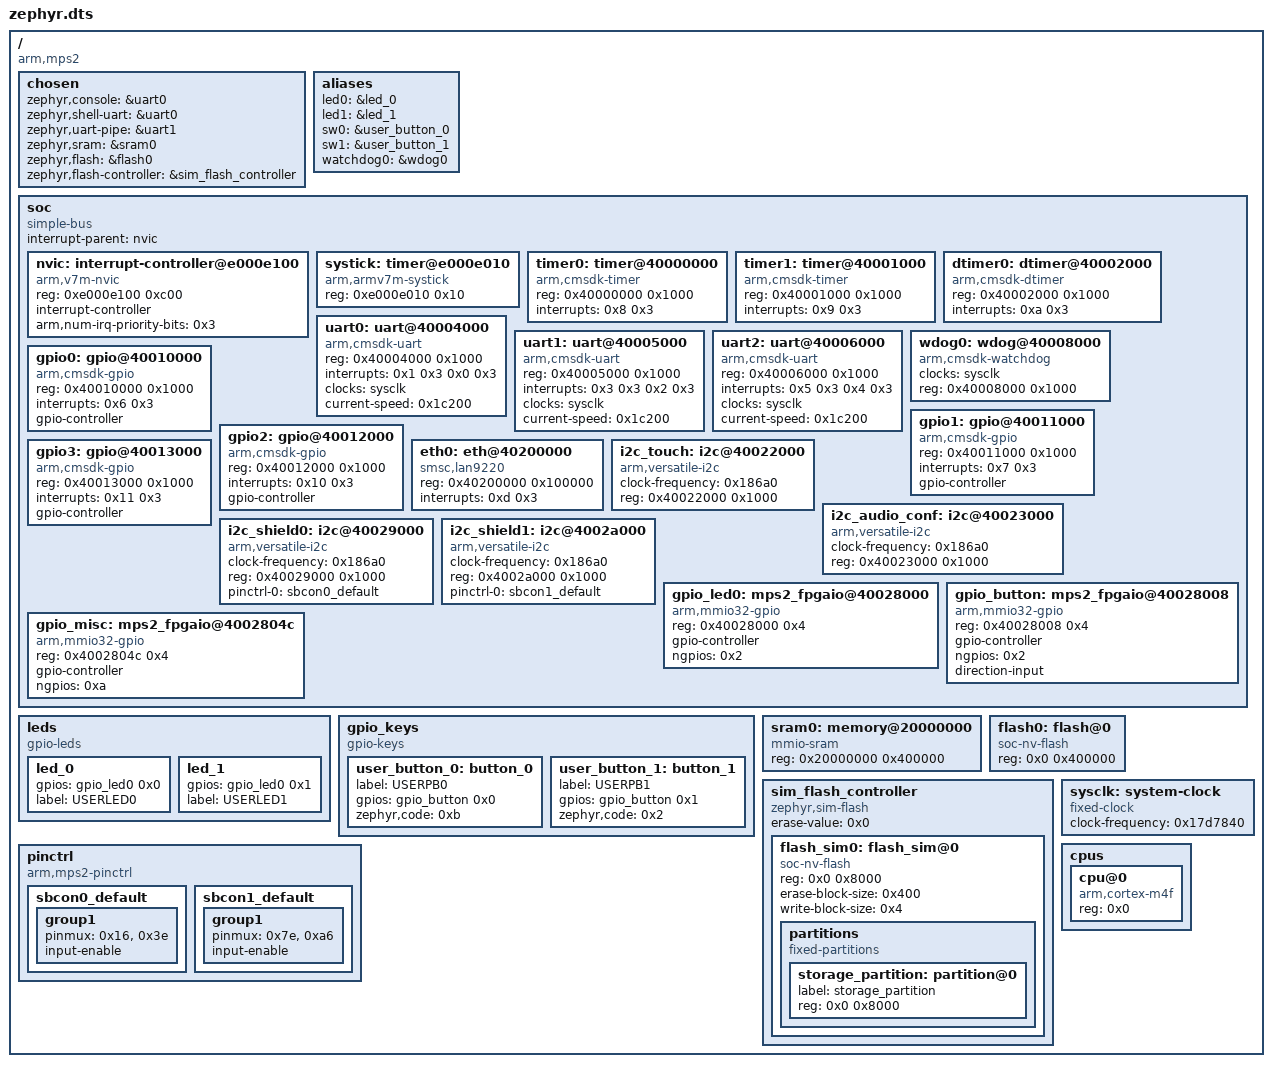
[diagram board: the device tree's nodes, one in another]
/dts-v1/;

/* node '/' defined in zephyr/dts/common/skeleton.dtsi:9 */
/ {
	compatible = "arm,mps2";  /* in zephyr/boards/arm/mps2/mps2_base.dtsi:5 */
	#address-cells = < 0x1 >; /* in zephyr/boards/arm/mps2/mps2_base.dtsi:6 */
	#size-cells = < 0x1 >;    /* in zephyr/boards/arm/mps2/mps2_base.dtsi:7 */

	/* node '/chosen' defined in zephyr/dts/common/skeleton.dtsi:13 */
	chosen {
		zephyr,console = &uart0;                         /* in zephyr/boards/arm/mps2/mps2_base.dtsi:18 */
		zephyr,shell-uart = &uart0;                      /* in zephyr/boards/arm/mps2/mps2_base.dtsi:19 */
		zephyr,uart-pipe = &uart1;                       /* in zephyr/boards/arm/mps2/mps2_base.dtsi:20 */
		zephyr,sram = &sram0;                            /* in zephyr/boards/arm/mps2/mps2_base.dtsi:21 */
		zephyr,flash = &flash0;                          /* in zephyr/boards/arm/mps2/mps2_base.dtsi:22 */
		zephyr,flash-controller = &sim_flash_controller; /* in zephyr/boards/arm/mps2/mps2_base.dtsi:23 */
	};

	/* node '/aliases' defined in zephyr/dts/common/skeleton.dtsi:15 */
	aliases {
		led0 = &led_0;        /* in zephyr/boards/arm/mps2/mps2_base.dtsi:10 */
		led1 = &led_1;        /* in zephyr/boards/arm/mps2/mps2_base.dtsi:11 */
		sw0 = &user_button_0; /* in zephyr/boards/arm/mps2/mps2_base.dtsi:12 */
		sw1 = &user_button_1; /* in zephyr/boards/arm/mps2/mps2_base.dtsi:13 */
		watchdog0 = &wdog0;   /* in zephyr/boards/arm/mps2/mps2_base.dtsi:14 */
	};

	/* node '/soc' defined in zephyr/dts/arm/armv7-m.dtsi:6 */
	soc {
		#address-cells = < 0x1 >;     /* in zephyr/dts/arm/armv7-m.dtsi:7 */
		#size-cells = < 0x1 >;        /* in zephyr/dts/arm/armv7-m.dtsi:8 */
		compatible = "simple-bus";    /* in zephyr/dts/arm/armv7-m.dtsi:9 */
		interrupt-parent = < &nvic >; /* in zephyr/dts/arm/armv7-m.dtsi:10 */
		ranges;                       /* in zephyr/dts/arm/armv7-m.dtsi:11 */

		/* node '/soc/interrupt-controller@e000e100' defined in zephyr/dts/arm/armv7-m.dtsi:13 */
		nvic: interrupt-controller@e000e100 {
			#address-cells = < 0x1 >;            /* in zephyr/dts/arm/armv7-m.dtsi:14 */
			compatible = "arm,v7m-nvic";         /* in zephyr/dts/arm/armv7-m.dtsi:15 */
			reg = < 0xe000e100 0xc00 >;          /* in zephyr/dts/arm/armv7-m.dtsi:16 */
			interrupt-controller;                /* in zephyr/dts/arm/armv7-m.dtsi:17 */
			#interrupt-cells = < 0x2 >;          /* in zephyr/dts/arm/armv7-m.dtsi:18 */
			arm,num-irq-priority-bits = < 0x3 >; /* in zephyr/boards/arm/mps2/mps2_base.dtsi:281 */
			phandle = < 0x1 >;                   /* in zephyr/dts/arm/armv7-m.dtsi:10 */
		};

		/* node '/soc/timer@e000e010' defined in zephyr/dts/arm/armv7-m.dtsi:21 */
		systick: timer@e000e010 {
			compatible = "arm,armv7m-systick"; /* in zephyr/dts/arm/armv7-m.dtsi:22 */
			reg = < 0xe000e010 0x10 >;         /* in zephyr/dts/arm/armv7-m.dtsi:23 */
		};

		/* node '/soc/timer@40000000' defined in zephyr/boards/arm/mps2/mps2_base.dtsi:98 */
		timer0: timer@40000000 {
			compatible = "arm,cmsdk-timer"; /* in zephyr/boards/arm/mps2/mps2_base.dtsi:99 */
			reg = < 0x40000000 0x1000 >;    /* in zephyr/boards/arm/mps2/mps2_base.dtsi:100 */
			interrupts = < 0x8 0x3 >;       /* in zephyr/boards/arm/mps2/mps2_base.dtsi:101 */
		};

		/* node '/soc/timer@40001000' defined in zephyr/boards/arm/mps2/mps2_base.dtsi:104 */
		timer1: timer@40001000 {
			compatible = "arm,cmsdk-timer"; /* in zephyr/boards/arm/mps2/mps2_base.dtsi:105 */
			reg = < 0x40001000 0x1000 >;    /* in zephyr/boards/arm/mps2/mps2_base.dtsi:106 */
			interrupts = < 0x9 0x3 >;       /* in zephyr/boards/arm/mps2/mps2_base.dtsi:107 */
		};

		/* node '/soc/dtimer@40002000' defined in zephyr/boards/arm/mps2/mps2_base.dtsi:110 */
		dtimer0: dtimer@40002000 {
			compatible = "arm,cmsdk-dtimer"; /* in zephyr/boards/arm/mps2/mps2_base.dtsi:111 */
			reg = < 0x40002000 0x1000 >;     /* in zephyr/boards/arm/mps2/mps2_base.dtsi:112 */
			interrupts = < 0xa 0x3 >;        /* in zephyr/boards/arm/mps2/mps2_base.dtsi:113 */
		};

		/* node '/soc/uart@40004000' defined in zephyr/boards/arm/mps2/mps2_base.dtsi:116 */
		uart0: uart@40004000 {
			compatible = "arm,cmsdk-uart";    /* in zephyr/boards/arm/mps2/mps2_base.dtsi:117 */
			reg = < 0x40004000 0x1000 >;      /* in zephyr/boards/arm/mps2/mps2_base.dtsi:118 */
			interrupts = < 0x1 0x3 0x0 0x3 >; /* in zephyr/boards/arm/mps2/mps2_base.dtsi:119 */
			interrupt-names = "tx",
			                  "rx";           /* in zephyr/boards/arm/mps2/mps2_base.dtsi:120 */
			clocks = < &sysclk >;             /* in zephyr/boards/arm/mps2/mps2_base.dtsi:121 */
			current-speed = < 0x1c200 >;      /* in zephyr/boards/arm/mps2/mps2_base.dtsi:122 */
		};

		/* node '/soc/uart@40005000' defined in zephyr/boards/arm/mps2/mps2_base.dtsi:125 */
		uart1: uart@40005000 {
			compatible = "arm,cmsdk-uart";    /* in zephyr/boards/arm/mps2/mps2_base.dtsi:126 */
			reg = < 0x40005000 0x1000 >;      /* in zephyr/boards/arm/mps2/mps2_base.dtsi:127 */
			interrupts = < 0x3 0x3 0x2 0x3 >; /* in zephyr/boards/arm/mps2/mps2_base.dtsi:128 */
			interrupt-names = "tx",
			                  "rx";           /* in zephyr/boards/arm/mps2/mps2_base.dtsi:129 */
			clocks = < &sysclk >;             /* in zephyr/boards/arm/mps2/mps2_base.dtsi:130 */
			current-speed = < 0x1c200 >;      /* in zephyr/boards/arm/mps2/mps2_base.dtsi:131 */
		};

		/* node '/soc/uart@40006000' defined in zephyr/boards/arm/mps2/mps2_base.dtsi:134 */
		uart2: uart@40006000 {
			compatible = "arm,cmsdk-uart";    /* in zephyr/boards/arm/mps2/mps2_base.dtsi:135 */
			reg = < 0x40006000 0x1000 >;      /* in zephyr/boards/arm/mps2/mps2_base.dtsi:136 */
			interrupts = < 0x5 0x3 0x4 0x3 >; /* in zephyr/boards/arm/mps2/mps2_base.dtsi:137 */
			interrupt-names = "tx",
			                  "rx";           /* in zephyr/boards/arm/mps2/mps2_base.dtsi:138 */
			clocks = < &sysclk >;             /* in zephyr/boards/arm/mps2/mps2_base.dtsi:139 */
			current-speed = < 0x1c200 >;      /* in zephyr/boards/arm/mps2/mps2_base.dtsi:140 */
		};

		/* node '/soc/wdog@40008000' defined in zephyr/boards/arm/mps2/mps2_base.dtsi:154 */
		wdog0: wdog@40008000 {
			compatible = "arm,cmsdk-watchdog"; /* in zephyr/boards/arm/mps2/mps2_base.dtsi:155 */
			clocks = < &sysclk >;              /* in zephyr/boards/arm/mps2/mps2_base.dtsi:156 */
			reg = < 0x40008000 0x1000 >;       /* in zephyr/boards/arm/mps2/mps2_base.dtsi:157 */
		};

		/* node '/soc/gpio@40010000' defined in zephyr/boards/arm/mps2/mps2_base.dtsi:171 */
		gpio0: gpio@40010000 {
			compatible = "arm,cmsdk-gpio"; /* in zephyr/boards/arm/mps2/mps2_base.dtsi:172 */
			reg = < 0x40010000 0x1000 >;   /* in zephyr/boards/arm/mps2/mps2_base.dtsi:173 */
			interrupts = < 0x6 0x3 >;      /* in zephyr/boards/arm/mps2/mps2_base.dtsi:174 */
			gpio-controller;               /* in zephyr/boards/arm/mps2/mps2_base.dtsi:175 */
			#gpio-cells = < 0x2 >;         /* in zephyr/boards/arm/mps2/mps2_base.dtsi:176 */
		};

		/* node '/soc/gpio@40011000' defined in zephyr/boards/arm/mps2/mps2_base.dtsi:179 */
		gpio1: gpio@40011000 {
			compatible = "arm,cmsdk-gpio"; /* in zephyr/boards/arm/mps2/mps2_base.dtsi:180 */
			reg = < 0x40011000 0x1000 >;   /* in zephyr/boards/arm/mps2/mps2_base.dtsi:181 */
			interrupts = < 0x7 0x3 >;      /* in zephyr/boards/arm/mps2/mps2_base.dtsi:182 */
			gpio-controller;               /* in zephyr/boards/arm/mps2/mps2_base.dtsi:183 */
			#gpio-cells = < 0x2 >;         /* in zephyr/boards/arm/mps2/mps2_base.dtsi:184 */
		};

		/* node '/soc/gpio@40012000' defined in zephyr/boards/arm/mps2/mps2_base.dtsi:187 */
		gpio2: gpio@40012000 {
			compatible = "arm,cmsdk-gpio"; /* in zephyr/boards/arm/mps2/mps2_base.dtsi:188 */
			reg = < 0x40012000 0x1000 >;   /* in zephyr/boards/arm/mps2/mps2_base.dtsi:189 */
			interrupts = < 0x10 0x3 >;     /* in zephyr/boards/arm/mps2/mps2_base.dtsi:190 */
			gpio-controller;               /* in zephyr/boards/arm/mps2/mps2_base.dtsi:191 */
			#gpio-cells = < 0x2 >;         /* in zephyr/boards/arm/mps2/mps2_base.dtsi:192 */
		};

		/* node '/soc/gpio@40013000' defined in zephyr/boards/arm/mps2/mps2_base.dtsi:195 */
		gpio3: gpio@40013000 {
			compatible = "arm,cmsdk-gpio"; /* in zephyr/boards/arm/mps2/mps2_base.dtsi:196 */
			reg = < 0x40013000 0x1000 >;   /* in zephyr/boards/arm/mps2/mps2_base.dtsi:197 */
			interrupts = < 0x11 0x3 >;     /* in zephyr/boards/arm/mps2/mps2_base.dtsi:198 */
			gpio-controller;               /* in zephyr/boards/arm/mps2/mps2_base.dtsi:199 */
			#gpio-cells = < 0x2 >;         /* in zephyr/boards/arm/mps2/mps2_base.dtsi:200 */
		};

		/* node '/soc/eth@40200000' defined in zephyr/boards/arm/mps2/mps2_base.dtsi:203 */
		eth0: eth@40200000 {
			compatible = "smsc,lan9220";   /* in zephyr/boards/arm/mps2/mps2_base.dtsi:205 */
			reg = < 0x40200000 0x100000 >; /* in zephyr/boards/arm/mps2/mps2_base.dtsi:208 */
			interrupts = < 0xd 0x3 >;      /* in zephyr/boards/arm/mps2/mps2_base.dtsi:209 */
		};

		/* node '/soc/i2c@40022000' defined in zephyr/boards/arm/mps2/mps2_base.dtsi:212 */
		i2c_touch: i2c@40022000 {
			compatible = "arm,versatile-i2c"; /* in zephyr/boards/arm/mps2/mps2_base.dtsi:213 */
			clock-frequency = < 0x186a0 >;    /* in zephyr/boards/arm/mps2/mps2_base.dtsi:214 */
			#address-cells = < 0x1 >;         /* in zephyr/boards/arm/mps2/mps2_base.dtsi:215 */
			#size-cells = < 0x0 >;            /* in zephyr/boards/arm/mps2/mps2_base.dtsi:216 */
			reg = < 0x40022000 0x1000 >;      /* in zephyr/boards/arm/mps2/mps2_base.dtsi:217 */
		};

		/* node '/soc/i2c@40023000' defined in zephyr/boards/arm/mps2/mps2_base.dtsi:220 */
		i2c_audio_conf: i2c@40023000 {
			compatible = "arm,versatile-i2c"; /* in zephyr/boards/arm/mps2/mps2_base.dtsi:221 */
			clock-frequency = < 0x186a0 >;    /* in zephyr/boards/arm/mps2/mps2_base.dtsi:222 */
			#address-cells = < 0x1 >;         /* in zephyr/boards/arm/mps2/mps2_base.dtsi:223 */
			#size-cells = < 0x0 >;            /* in zephyr/boards/arm/mps2/mps2_base.dtsi:224 */
			reg = < 0x40023000 0x1000 >;      /* in zephyr/boards/arm/mps2/mps2_base.dtsi:225 */
		};

		/* node '/soc/i2c@40029000' defined in zephyr/boards/arm/mps2/mps2_base.dtsi:228 */
		i2c_shield0: i2c@40029000 {
			compatible = "arm,versatile-i2c"; /* in zephyr/boards/arm/mps2/mps2_base.dtsi:229 */
			clock-frequency = < 0x186a0 >;    /* in zephyr/boards/arm/mps2/mps2_base.dtsi:230 */
			#address-cells = < 0x1 >;         /* in zephyr/boards/arm/mps2/mps2_base.dtsi:231 */
			#size-cells = < 0x0 >;            /* in zephyr/boards/arm/mps2/mps2_base.dtsi:232 */
			reg = < 0x40029000 0x1000 >;      /* in zephyr/boards/arm/mps2/mps2_base.dtsi:233 */
			pinctrl-0 = < &sbcon0_default >;  /* in zephyr/boards/arm/mps2/mps2_base.dtsi:234 */
			pinctrl-names = "default";        /* in zephyr/boards/arm/mps2/mps2_base.dtsi:235 */
		};

		/* node '/soc/i2c@4002a000' defined in zephyr/boards/arm/mps2/mps2_base.dtsi:238 */
		i2c_shield1: i2c@4002a000 {
			compatible = "arm,versatile-i2c"; /* in zephyr/boards/arm/mps2/mps2_base.dtsi:239 */
			clock-frequency = < 0x186a0 >;    /* in zephyr/boards/arm/mps2/mps2_base.dtsi:240 */
			#address-cells = < 0x1 >;         /* in zephyr/boards/arm/mps2/mps2_base.dtsi:241 */
			#size-cells = < 0x0 >;            /* in zephyr/boards/arm/mps2/mps2_base.dtsi:242 */
			reg = < 0x4002a000 0x1000 >;      /* in zephyr/boards/arm/mps2/mps2_base.dtsi:243 */
			pinctrl-0 = < &sbcon1_default >;  /* in zephyr/boards/arm/mps2/mps2_base.dtsi:244 */
			pinctrl-names = "default";        /* in zephyr/boards/arm/mps2/mps2_base.dtsi:245 */
		};

		/* node '/soc/mps2_fpgaio@40028000' defined in zephyr/boards/arm/mps2/mps2_base.dtsi:248 */
		gpio_led0: mps2_fpgaio@40028000 {
			compatible = "arm,mmio32-gpio"; /* in zephyr/boards/arm/mps2/mps2_base.dtsi:249 */
			reg = < 0x40028000 0x4 >;       /* in zephyr/boards/arm/mps2/mps2_base.dtsi:250 */
			gpio-controller;                /* in zephyr/boards/arm/mps2/mps2_base.dtsi:251 */
			#gpio-cells = < 0x1 >;          /* in zephyr/boards/arm/mps2/mps2_base.dtsi:252 */
			ngpios = < 0x2 >;               /* in zephyr/boards/arm/mps2/mps2_base.dtsi:253 */
			phandle = < 0x5 >;              /* in zephyr/boards/arm/mps2/mps2_base.dtsi:30 */
		};

		/* node '/soc/mps2_fpgaio@40028008' defined in zephyr/boards/arm/mps2/mps2_base.dtsi:256 */
		gpio_button: mps2_fpgaio@40028008 {
			compatible = "arm,mmio32-gpio"; /* in zephyr/boards/arm/mps2/mps2_base.dtsi:257 */
			reg = < 0x40028008 0x4 >;       /* in zephyr/boards/arm/mps2/mps2_base.dtsi:258 */
			gpio-controller;                /* in zephyr/boards/arm/mps2/mps2_base.dtsi:259 */
			#gpio-cells = < 0x1 >;          /* in zephyr/boards/arm/mps2/mps2_base.dtsi:260 */
			ngpios = < 0x2 >;               /* in zephyr/boards/arm/mps2/mps2_base.dtsi:261 */
			direction-input;                /* in zephyr/boards/arm/mps2/mps2_base.dtsi:262 */
			phandle = < 0x6 >;              /* in zephyr/boards/arm/mps2/mps2_base.dtsi:45 */
		};

		/* node '/soc/mps2_fpgaio@4002804c' defined in zephyr/boards/arm/mps2/mps2_base.dtsi:265 */
		gpio_misc: mps2_fpgaio@4002804c {
			compatible = "arm,mmio32-gpio"; /* in zephyr/boards/arm/mps2/mps2_base.dtsi:266 */
			reg = < 0x4002804c 0x4 >;       /* in zephyr/boards/arm/mps2/mps2_base.dtsi:267 */
			gpio-controller;                /* in zephyr/boards/arm/mps2/mps2_base.dtsi:268 */
			#gpio-cells = < 0x1 >;          /* in zephyr/boards/arm/mps2/mps2_base.dtsi:269 */
			ngpios = < 0xa >;               /* in zephyr/boards/arm/mps2/mps2_base.dtsi:270 */
		};
	};

	/* node '/leds' defined in zephyr/boards/arm/mps2/mps2_base.dtsi:26 */
	leds {
		compatible = "gpio-leds"; /* in zephyr/boards/arm/mps2/mps2_base.dtsi:27 */

		/* node '/leds/led_0' defined in zephyr/boards/arm/mps2/mps2_base.dtsi:29 */
		led_0: led_0 {
			gpios = < &gpio_led0 0x0 >; /* in zephyr/boards/arm/mps2/mps2_base.dtsi:30 */
			label = "USERLED0";         /* in zephyr/boards/arm/mps2/mps2_base.dtsi:31 */
		};

		/* node '/leds/led_1' defined in zephyr/boards/arm/mps2/mps2_base.dtsi:34 */
		led_1: led_1 {
			gpios = < &gpio_led0 0x1 >; /* in zephyr/boards/arm/mps2/mps2_base.dtsi:35 */
			label = "USERLED1";         /* in zephyr/boards/arm/mps2/mps2_base.dtsi:36 */
		};
	};

	/* node '/gpio_keys' defined in zephyr/boards/arm/mps2/mps2_base.dtsi:40 */
	gpio_keys {
		compatible = "gpio-keys"; /* in zephyr/boards/arm/mps2/mps2_base.dtsi:41 */

		/* node '/gpio_keys/button_0' defined in zephyr/boards/arm/mps2/mps2_base.dtsi:43 */
		user_button_0: button_0 {
			label = "USERPB0";            /* in zephyr/boards/arm/mps2/mps2_base.dtsi:44 */
			gpios = < &gpio_button 0x0 >; /* in zephyr/boards/arm/mps2/mps2_base.dtsi:45 */
			zephyr,code = < 0xb >;        /* in zephyr/boards/arm/mps2/mps2_base.dtsi:46 */
		};

		/* node '/gpio_keys/button_1' defined in zephyr/boards/arm/mps2/mps2_base.dtsi:49 */
		user_button_1: button_1 {
			label = "USERPB1";            /* in zephyr/boards/arm/mps2/mps2_base.dtsi:50 */
			gpios = < &gpio_button 0x1 >; /* in zephyr/boards/arm/mps2/mps2_base.dtsi:51 */
			zephyr,code = < 0x2 >;        /* in zephyr/boards/arm/mps2/mps2_base.dtsi:52 */
		};
	};

	/* node '/memory@20000000' defined in zephyr/boards/arm/mps2/mps2_base.dtsi:56 */
	sram0: memory@20000000 {
		compatible = "mmio-sram";      /* in zephyr/boards/arm/mps2/mps2_base.dtsi:57 */
		reg = < 0x20000000 0x400000 >; /* in zephyr/boards/arm/mps2/mps2_base.dtsi:58 */
	};

	/* node '/flash@0' defined in zephyr/boards/arm/mps2/mps2_base.dtsi:61 */
	flash0: flash@0 {
		compatible = "soc-nv-flash"; /* in zephyr/boards/arm/mps2/mps2_base.dtsi:62 */
		reg = < 0x0 0x400000 >;      /* in zephyr/boards/arm/mps2/mps2_base.dtsi:63 */
	};

	/* node '/sim_flash_controller' defined in zephyr/boards/arm/mps2/mps2_base.dtsi:66 */
	sim_flash_controller: sim_flash_controller {
		compatible = "zephyr,sim-flash"; /* in zephyr/boards/arm/mps2/mps2_base.dtsi:67 */
		#address-cells = < 0x1 >;        /* in zephyr/boards/arm/mps2/mps2_base.dtsi:68 */
		#size-cells = < 0x1 >;           /* in zephyr/boards/arm/mps2/mps2_base.dtsi:69 */
		erase-value = < 0x0 >;           /* in zephyr/boards/arm/mps2/mps2_base.dtsi:70 */

		/* node '/sim_flash_controller/flash_sim@0' defined in zephyr/boards/arm/mps2/mps2_base.dtsi:72 */
		flash_sim0: flash_sim@0 {
			compatible = "soc-nv-flash";  /* in zephyr/boards/arm/mps2/mps2_base.dtsi:73 */
			reg = < 0x0 0x8000 >;         /* in zephyr/boards/arm/mps2/mps2_base.dtsi:74 */
			erase-block-size = < 0x400 >; /* in zephyr/boards/arm/mps2/mps2_base.dtsi:75 */
			write-block-size = < 0x4 >;   /* in zephyr/boards/arm/mps2/mps2_base.dtsi:76 */

			/* node '/sim_flash_controller/flash_sim@0/partitions' defined in zephyr/boards/arm/mps2/mps2_base.dtsi:78 */
			partitions {
				compatible = "fixed-partitions"; /* in zephyr/boards/arm/mps2/mps2_base.dtsi:79 */
				#address-cells = < 0x1 >;        /* in zephyr/boards/arm/mps2/mps2_base.dtsi:80 */
				#size-cells = < 0x1 >;           /* in zephyr/boards/arm/mps2/mps2_base.dtsi:81 */

				/* node '/sim_flash_controller/flash_sim@0/partitions/partition@0' defined in zephyr/boards/arm/mps2/mps2_base.dtsi:83 */
				storage_partition: partition@0 {
					label = "storage_partition"; /* in zephyr/boards/arm/mps2/mps2_base.dtsi:84 */
					reg = < 0x0 0x8000 >;        /* in zephyr/boards/arm/mps2/mps2_base.dtsi:85 */
				};
			};
		};
	};

	/* node '/system-clock' defined in zephyr/boards/arm/mps2/mps2_base.dtsi:91 */
	sysclk: system-clock {
		compatible = "fixed-clock";      /* in zephyr/boards/arm/mps2/mps2_base.dtsi:92 */
		clock-frequency = < 0x17d7840 >; /* in zephyr/boards/arm/mps2/mps2_base.dtsi:93 */
		#clock-cells = < 0x0 >;          /* in zephyr/boards/arm/mps2/mps2_base.dtsi:94 */
		phandle = < 0x2 >;               /* in zephyr/boards/arm/mps2/mps2_base.dtsi:121 */
	};

	/* node '/pinctrl' defined in zephyr/boards/arm/mps2/mps2_base.dtsi:274 */
	pinctrl: pinctrl {
		compatible = "arm,mps2-pinctrl"; /* in zephyr/boards/arm/mps2/mps2_base.dtsi:275 */
		status = "okay";                 /* in zephyr/boards/arm/mps2/mps2_base.dtsi:276 */

		/* node '/pinctrl/sbcon0_default' defined in zephyr/boards/arm/mps2/mps2-pinctrl.dtsi:56 */
		sbcon0_default: sbcon0_default {
			phandle = < 0x3 >; /* in zephyr/boards/arm/mps2/mps2_base.dtsi:234 */

			/* node '/pinctrl/sbcon0_default/group1' defined in zephyr/boards/arm/mps2/mps2-pinctrl.dtsi:57 */
			group1 {
				pinmux = < 0x16 >,
				         < 0x3e >; /* in zephyr/boards/arm/mps2/mps2-pinctrl.dtsi:58 */
				input-enable;      /* in zephyr/boards/arm/mps2/mps2-pinctrl.dtsi:59 */
			};
		};

		/* node '/pinctrl/sbcon1_default' defined in zephyr/boards/arm/mps2/mps2-pinctrl.dtsi:63 */
		sbcon1_default: sbcon1_default {
			phandle = < 0x4 >; /* in zephyr/boards/arm/mps2/mps2_base.dtsi:244 */

			/* node '/pinctrl/sbcon1_default/group1' defined in zephyr/boards/arm/mps2/mps2-pinctrl.dtsi:64 */
			group1 {
				pinmux = < 0x7e >,
				         < 0xa6 >; /* in zephyr/boards/arm/mps2/mps2-pinctrl.dtsi:65 */
				input-enable;      /* in zephyr/boards/arm/mps2/mps2-pinctrl.dtsi:66 */
			};
		};
	};

	/* node '/cpus' defined in zephyr/boards/arm/mps2/mps2_an386.dts:20 */
	cpus {
		#address-cells = < 0x1 >; /* in zephyr/boards/arm/mps2/mps2_an386.dts:21 */
		#size-cells = < 0x0 >;    /* in zephyr/boards/arm/mps2/mps2_an386.dts:22 */

		/* node '/cpus/cpu@0' defined in zephyr/boards/arm/mps2/mps2_an386.dts:24 */
		cpu@0 {
			compatible = "arm,cortex-m4f"; /* in zephyr/boards/arm/mps2/mps2_an386.dts:25 */
			reg = < 0x0 >;                 /* in zephyr/boards/arm/mps2/mps2_an386.dts:26 */
		};
	};
};
